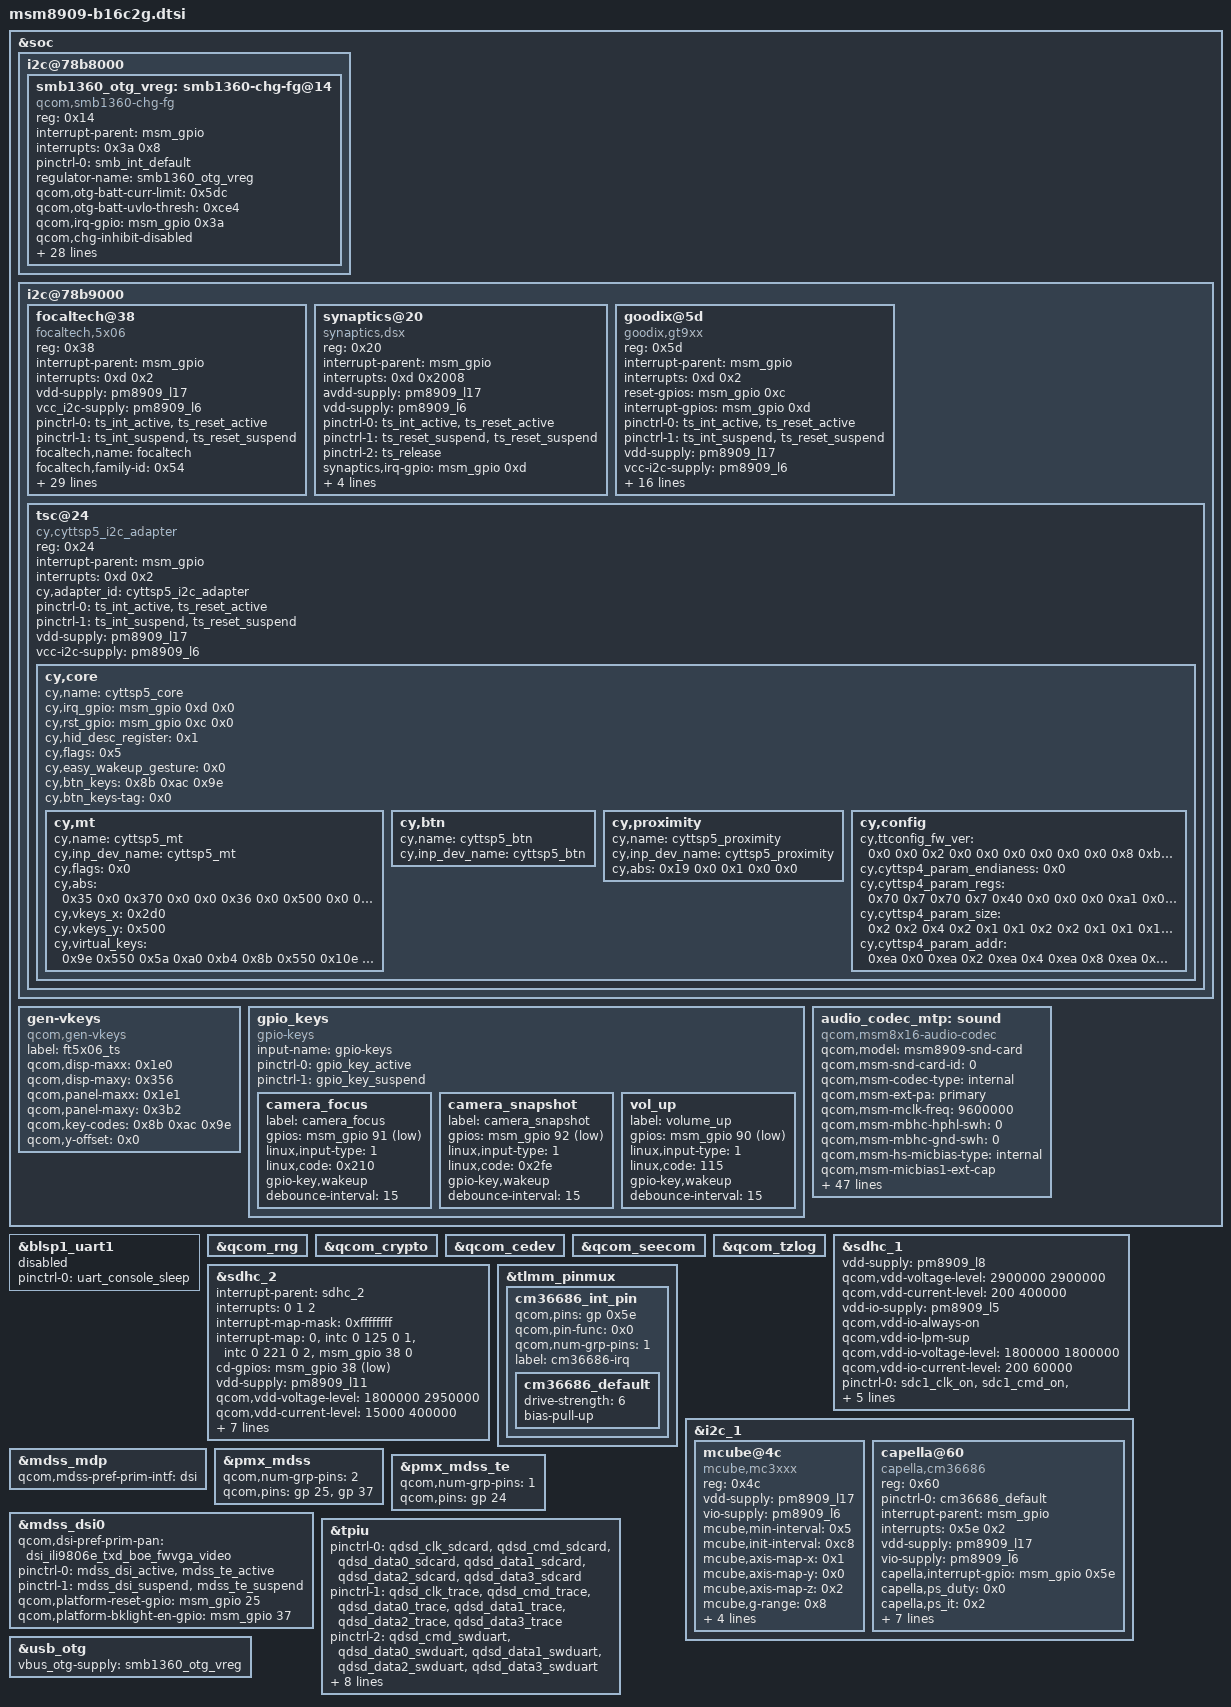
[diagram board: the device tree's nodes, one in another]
/* Copyright (c) 2014-2015, The Linux Foundation. All rights reserved.
 *
 * This program is free software; you can redistribute it and/or modify
 * it under the terms of the GNU General Public License version 2 and
 * only version 2 as published by the Free Software Foundation.
 *
 * This program is distributed in the hope that it will be useful,
 * but WITHOUT ANY WARRANTY; without even the implied warranty of
 * MERCHANTABILITY or FITNESS FOR A PARTICULAR PURPOSE.  See the
 * GNU General Public License for more details.
 */

#include "../msm8909-camera-sensor-mtp.dtsi"

&soc {
	/*
	 * DT node to add support for SMB136x charger and integrate
	 * with VM-BMS.
	 */
	i2c@78b8000 {
		smb1360_otg_vreg: smb1360-chg-fg@14 {
			compatible = "qcom,smb1360-chg-fg";
			reg = <0x14>;
			interrupt-parent = <&msm_gpio>;
			interrupts = <0x3a 0x8>;
			pinctrl-names = "default";
			pinctrl-0 = <&smb_int_default>;
			regulator-name = "smb1360_otg_vreg";
			qcom,otg-batt-curr-limit = <0x5dc>;
			qcom,otg-batt-uvlo-thresh = <0xce4>;
			qcom,irq-gpio = <&msm_gpio 0x3a 0x8>;
			qcom,chg-inhibit-disabled;
			qcom,rsense-10mhom;
			qcom,cpu0-sensor-name = "tsens_tz_sensor3";
			qcom,cpu0-temp-max = <0x38>;
			qcom,cpu0-temp-min = <0x34>;
			qcom,qpnp-vadc = <&pm8909_vadc>;
			qcom,float-voltage-mv = <0x10fe>;
			qcom,iterm-ma = <0x64>;
			qcom,recharge-thresh-mv = <0x64>;
			qcom,thermal-mitigation = <0x5dc 0x2bc 0x258 0x0>;
			qcom,charging-timeout = <0x600>;
			qcom,fg-cutoff-voltage-mv = <0xd48>;
			qcom,fg-voltage-empty-mv = <0xcb2>;
			qcom,fg-batt-capacity-mah = <0x76c>;
			qcom,fg-cc-soc-coeff = <0x8850>;
			qcom,fg-auto-recharge-soc = <0x63>;
			qcom,fg-reset-thresold-mv = <0x32>;
			qcom,shdn-after-pwroff;
			qcom,fg-reset-at-pon;
			qcom,config-hard-thresholds;
			qcom,cold-bat-decidegc = <0xffffffb0>;
			qcom,hot-bat-decidegc = <0x230>;
			qcom,soft-jeita-supported;
			qcom,warm-bat-decidegc = <0x1c2>;
			qcom,cool-bat-decidegc = <0x64>;
			qcom,cool-bat-mv = <0x10fe>;
			qcom,warm-bat-mv = <0x10fe>;
			qcom,cool-bat-ma = <0x190>;
			qcom,warm-bat-ma = <0x258>;
		};
	};

	i2c@78b9000 { /* BLSP1 QUP5 */
		focaltech@38 {
			compatible = "focaltech,5x06";
			reg = <0x38>;
			interrupt-parent = <&msm_gpio>;
			interrupts = <0xd 0x2>;
			vdd-supply = <&pm8909_l17>;
			vcc_i2c-supply = <&pm8909_l6>;
			pinctrl-names = "pmx_ts_active", "pmx_ts_suspend";
			pinctrl-0 = <&ts_int_active &ts_reset_active>;
			pinctrl-1 = <&ts_int_suspend &ts_reset_suspend>;
			focaltech,name = "focaltech";
			focaltech,family-id = <0x54>;
			focaltech,reset-gpio = <&msm_gpio 0xc 0x0>;
			focaltech,irq-gpio = <&msm_gpio 0xd 0x2>;
			focaltech,display-coords = <0x0 0x0 0x1e0 0x356>;
			focaltech,panel-coords = <0x0 0x0 0x1e0 0x356>;
			focaltech,button-map = <0x8b 0xac 0x9e>;
			focaltech,gesture-func-map = <0x1fd 0x1fe 0x1ff 0x200 0x201 0x202 0x203 0x204 0x208 0x207>;
			focaltech,gesture-figure-map = <0x24 0x52 0x51 0x30 0x54 0x31 0x46 0x41 0x32 0x33>;
			focaltech,gesture-reg-map = <0xd1 0xd2 0xd5 0xd6 0xd7 0xd8>;
			focaltech,gesture-reg-value-map = <0x30 0x1f 0x42 0x16 0x0 0x20>;
			focaltech,fw-rawdata-range = <0x0 0x0>;
			focaltech,no-force-update;
			focaltech,i2c-pull-up;
			focaltech,group-id = <0x1>;
			focaltech,hard-reset-delay-ms = <0x5>;
			focaltech,soft-reset-delay-ms = <0xc8>;
			focaltech,num-max-touches = <0x5>;
			focaltech,fw-name = "fw_ft5x06_0xFF.bin";
			focaltech,fw-delay-aa-ms = <0x2>;
			focaltech,fw-delay-55-ms = <0x2>;
			focaltech,fw-upgrade-id1 = <0x54>;
			focaltech,fw-upgrade-id2 = <0x2c>;
			focaltech,fw-delay-readid-ms = <0x14>;
			focaltech,fw-delay-era-flsh-ms = <0xbb8>;
			focaltech,fw-panelid-command = <0x300d784>;
			focaltech,touch-area-param = <0x7>;
		};

		synaptics@20 {
			compatible = "synaptics,dsx";
			reg = <0x20>;
			interrupt-parent = <&msm_gpio>;
			interrupts = <0xd 0x2008>;
			avdd-supply = <&pm8909_l17>;
			vdd-supply = <&pm8909_l6>;
			pinctrl-names = "pmx_ts_active", "pmx_ts_suspend", "pmx_ts_release";
			pinctrl-0 = <&ts_int_active &ts_reset_active>;
			pinctrl-1 = <&ts_reset_suspend &ts_reset_suspend>;
			pinctrl-2 = <&ts_release>;
			synaptics,irq-gpio = <&msm_gpio 0xd 0x2008>;
			synaptics,reset-gpio = <&msm_gpio 0xc 0x0>;
			synaptics,disable-gpios;
			synaptics,display-coords = <0x0 0x0 0x2cf 0x4ff>;
			synaptics,panel-coords = <0x0 0x0 0x2cf 0x57d>;
		};

		goodix@5d {
			compatible = "goodix,gt9xx";
			reg = <0x5d>;
			interrupt-parent = <&msm_gpio>;
			interrupts = <0xd 0x2>;
			reset-gpios = <&msm_gpio 0xc 0x0>;
			interrupt-gpios = <&msm_gpio 0xd 0x0>;
			pinctrl-names = "pmx_ts_active", "pmx_ts_suspend";
			pinctrl-0 = <&ts_int_active &ts_reset_active>;
			pinctrl-1 = <&ts_int_suspend &ts_reset_suspend>;
			vdd-supply = <&pm8909_l17>;
			vcc-i2c-supply = <&pm8909_l6>;
			goodix,panel-coords = <0x0 0x0 0x2d0 0x500>;
			goodix,display-coords = <0x0 0x0 0x2d0 0x500>;
			goodix,button-map = <0x8b 0xac 0x9e>;
			goodix,gesture-map = <0x1fd 0x1fe 0x1ff 0x200 0x201 0x202 0x203 0x204 0x205 0x206>;
			goodix,gesture-key = <0xcc 0x3e 0x63 0x6f 0x76 0x77 0x73 0x7a 0x6d 0x5e>;
			goodix,product-id = "9157";
			goodix,cfg-data1 = [4a d0 02 00 05 0a 35 41 01 42 28 0c 53 35 03 07 00 00 1f 7e 00 00 06 12 18 1e 14 8b 0a 0c 34 00 d3 07 00 00 00 ba 33 11 3c 01 00 00 00 00 00 00 00 00 2a 31 4e 54 c5 01 00 14 00 04 82 33 00 79 38 00 71 3d 00 6a 43 00 64 4a 00 64 10 38 50 00 f0 4a 3a ff ff 27 00 00 00 00 00 00 00 00 00 00 00 00 00 0a 14 04 05 10 32 64 09 14 00 00 4b 32 02 04 06 08 0a 0c 0e 10 12 14 16 18 ff ff 00 00 00 00 00 00 00 00 00 00 00 23 00 02 00 00 1e 1f 1d 20 1c 21 18 22 24 16 13 0a 08 12 06 10 04 0f 02 0c 00 ff ff ff ff ff 00 00 00 f6 ff ff ff ff ff ff ff ff 8f ff ff ff 5a 01];
			goodix,cfg-data2 = [48 d0 02 00 05 05 35 41 01 42 28 0c 55 37 03 07 00 00 1f 7e 00 00 06 12 18 1e 14 8b 0a 0c 34 00 d3 07 00 00 00 ba 33 11 3c 01 00 00 00 00 00 00 00 00 2a 31 4e 54 c5 01 00 14 00 04 82 33 00 79 38 00 71 3d 00 6a 43 00 64 4a 00 64 10 38 50 00 f0 4a 3a ff ff 27 00 00 00 00 00 00 00 00 00 00 00 00 00 0a 0f 04 26 00 21 84 0c 14 00 00 4b 32 02 04 06 08 0a 0c 0e 10 12 14 16 18 ff ff 1f ff ff ff ff ff ff ff ff 00 00 23 00 02 ff 00 24 16 22 18 21 1c 20 1d 1e 1f 13 02 04 12 06 10 08 0f 0a 0c 00 ff ff ff ff ff 00 00 00 f4 ff ff ff ff ff ff ff ff 4f ff ff ff 6b 01];
			goodix,test-data1 = [41 d0 02 00 05 0a 05 41 01 08 28 05 50 32 03 05 00 00 00 00 00 00 00 00 00 00 00 8b 2a 0c 5b 5e 61 07 00 00 00 98 03 2d 00 00 00 00 00 00 00 00 00 00 00 00 00 00 40 00 00 00 00 00 00 00 00 00 00 00 00 00 00 00 00 00 00 00 00 00 10 38 50 00 f0 4a 3a ff ff 27 00 00 00 00 00 00 00 00 00 00 00 00 00 00 00 00 00 00 00 00 00 00 00 00 00 00 02 04 06 08 0a 0c 0e 10 12 14 16 18 ff ff 00 00 00 00 00 00 00 00 00 ff 00 00 00 00 ff 00 1e 1f 1d 20 1c 21 18 22 16 24 13 0a 08 12 06 10 04 0f 02 0c 00 ff ff ff ff ff ff 00 00 fb 00 01 f0 11 00 ff 00 11 e1 00 00 00 a4 01];
			goodix,test-data2 = [00 d0 02 38 04 05 05 41 01 08 28 05 50 32 03 05 00 00 00 00 00 00 00 00 00 00 00 8b 0a 0c 79 7b d3 07 00 00 00 99 03 11 00 00 00 00 00 00 00 00 00 00 00 00 00 00 40 00 00 00 00 00 00 00 00 00 00 00 00 00 00 00 00 00 00 00 00 00 10 38 50 00 f0 4a 3a ff ff 27 00 00 00 00 00 00 00 00 00 00 00 00 00 00 00 00 00 00 00 00 00 00 00 00 00 00 02 04 06 08 0a 0c 0e 10 12 14 16 18 ff ff 1f ff ff ff ff ff ff ff ff 00 ff ff ff ff ff 00 24 16 22 18 21 1c 20 1d 1e 1f 13 02 04 12 06 10 08 0f 0a 0c 00 ff ff ff ff ff 00 ff ff fb ff ff ff ff ff ff ff ff bf ff ff ff 6d 01];
		};

		tsc@24 {
			compatible = "cy,cyttsp5_i2c_adapter";
			reg = <0x24>;
			interrupt-parent = <&msm_gpio>;
			interrupts = <0xd 0x2>;
			cy,adapter_id = "cyttsp5_i2c_adapter";
			pinctrl-names = "pmx_ts_active", "pmx_ts_suspend";
			pinctrl-0 = <&ts_int_active &ts_reset_active>;
			pinctrl-1 = <&ts_int_suspend &ts_reset_suspend>;
			vdd-supply = <&pm8909_l17>;
			vcc-i2c-supply = <&pm8909_l6>;

			cy,core {
				cy,name = "cyttsp5_core";
				cy,irq_gpio = <&msm_gpio 0xd 0x0>;
				cy,rst_gpio = <&msm_gpio 0xc 0x0>;
				cy,hid_desc_register = <0x1>;
				cy,flags = <0x5>;
				cy,easy_wakeup_gesture = <0x0>;
				cy,btn_keys = <0x8b 0xac 0x9e>;
				cy,btn_keys-tag = <0x0>;

				cy,mt {
					cy,name = "cyttsp5_mt";
					cy,inp_dev_name = "cyttsp5_mt";
					cy,flags = <0x0>;
					cy,abs = <0x35 0x0 0x370 0x0 0x0 0x36 0x0 0x500 0x0 0x0 0x3a 0x0 0xff 0x0 0x0 0xffff 0x0 0xff 0x0 0x0 0x39 0x0 0xf 0x0 0x0 0x30 0x0 0xff 0x0 0x0 0x31 0x0 0xff 0x0 0x0 0x34 0xffffff81 0x7f 0x0 0x0 0x37 0x0 0x1 0x0 0x0 0x19 0x0 0xff 0x0 0x0>;
					cy,vkeys_x = <0x2d0>;
					cy,vkeys_y = <0x500>;
					cy,virtual_keys = <0x9e 0x550 0x5a 0xa0 0xb4 0x8b 0x550 0x10e 0xa0 0xb4 0xac 0x550 0x1c2 0xa0 0xb4 0xd9 0x550 0x276 0xa0 0xb4>;
				};

				cy,btn {
					cy,name = "cyttsp5_btn";
					cy,inp_dev_name = "cyttsp5_btn";
				};

				cy,proximity {
					cy,name = "cyttsp5_proximity";
					cy,inp_dev_name = "cyttsp5_proximity";
					cy,abs = <0x19 0x0 0x1 0x0 0x0>;
				};

				cy,config {
					cy,ttconfig_fw_ver = <0x0 0x0 0x2 0x0 0x0 0x0 0x0 0x0 0x0 0x8 0xbf 0x3d 0xc 0x7 0x12 0x9c 0x0 0xa1>;
					cy,cyttsp4_param_endianess = <0x0>;
					cy,cyttsp4_param_regs = <0x70 0x7 0x70 0x7 0x40 0x0 0x0 0x0 0xa1 0x0 0x3 0x0 0x7c 0x14 0xfc 0x21 0x14 0x0 0x1 0x8 0x3 0x0 0x0 0x0 0x64 0x0 0xe8 0x3 0x1 0xc 0x64 0x8 0xf4 0x1 0x1e 0x0 0x88 0x13 0x3 0x3c 0x14 0x3c 0x0 0x0 0x0 0xa 0x0 0x0 0x0 0x0 0x0 0x0 0x0 0x0 0x0 0xff 0x0 0x1 0x0 0x1 0x32 0x0 0xfa 0x0 0x0 0x0 0x0 0x0 0x0 0x0 0x0 0x0 0x0 0x0 0x0 0x0 0x0 0x0 0x0 0x0 0x1 0x0 0x0 0x0 0x0 0x0 0x0 0x0 0x64 0x0 0x2 0x1 0x0 0x0 0x0 0x0 0x0 0x0 0x6 0x6 0xb4 0x0 0x5a 0x0 0xe8 0x3 0x0 0x0 0x1 0x0 0x7f 0x0 0x2d 0x0 0x1 0x60 0x0 0x80 0x1 0xff 0x0 0x0 0x0 0x0 0x30 0x0 0x90 0x1 0x0 0x7f 0x4 0x1 0x1f 0x2 0x0 0x0 0x38 0x0 0x90 0x1 0x0 0x7f 0x4 0x1 0x1f 0x2 0x0 0x0 0x3c 0x0 0x90 0x1 0x0 0x7f 0x4 0x1 0x1f 0x2 0x0 0x0 0x3f 0x0 0x90 0x1 0x0 0x7f 0x4 0x1 0x1f 0x2 0x0 0x0 0x4b 0x0 0x90 0x1 0x0 0x7f 0x4 0x1 0x1f 0x2 0x0 0x0 0x2c 0x0 0x0 0x0 0xf0 0x0 0x0 0x0 0x2 0x0 0x0 0x0 0x1 0x0 0x0 0x0 0xff 0xff 0x1 0x0 0xf0 0x0 0x0 0x0 0x2 0x0 0x0 0x0 0x2 0x0 0x0 0x0 0xff 0xff 0x1 0x0 0x0 0xc 0x0 0x0 0x0 0x0 0x0 0x0 0x0 0x0 0x0 0x0 0x10 0x0 0x0 0x0 0x0 0x0 0x0 0x0 0x4 0x17 0x3 0x0 0x0 0x0 0x0 0x0 0xe0 0x1 0x0 0x0 0x20 0x3 0x0 0x0 0x0 0x0 0x0 0x0 0x0 0x0 0x2 0x1 0x2 0x58 0x80 0x0 0x1a 0x0 0x4 0x0 0x1a 0x0 0x0 0x4 0x38 0x0 0x5 0x4 0xf 0x28 0x0 0x0 0x0 0x0 0x0 0x0 0x8 0x78 0x2 0x0 0x5 0x0 0x2 0x0 0x4a 0x1 0x0 0x0 0x82 0x0 0x0 0x0 0x4a 0x1 0x0 0x0 0x82 0x0 0x0 0x0 0x78 0x0 0x0 0x0 0xb4 0x0 0x0 0x0 0x78 0x0 0x0 0x0 0xb4 0x0 0x0 0x0 0x0 0xa 0x64 0x0 0x78 0x0 0x3 0x4 0x3 0x68 0x80 0x40 0x4 0x19 0x0 0x0 0x28 0x28 0x28 0x28 0x28 0x28 0x28 0x28 0xa 0x14 0x0 0x0 0x0 0x0 0x0 0x0 0x0 0x0 0x0 0x0 0x77 0x70 0x0 0x1 0x0 0x1 0xa 0x0 0xa 0x0 0x14 0x0 0x14 0x0 0x28 0x0 0x77 0x70 0x1 0x1 0x1 0x1 0x14 0x0 0x14 0x0 0x14 0x0 0x14 0x0 0x3c 0x0 0x0 0x0 0x0 0x0 0x0 0x0 0x0 0x0 0x0 0x0 0x0 0x0 0x0 0x0 0x0 0x0 0xc8 0x0 0x0 0x0 0x5 0x5 0x14 0x3 0xf 0x0 0xa 0x0 0xa 0x0 0xa 0x0 0xa 0x0 0x5 0x0 0x50 0x50 0x50 0x50 0x50 0x3 0x78 0x0 0xc 0x0 0xc 0x0 0xc 0x0 0x0 0x1 0x1 0x0 0x40 0x1f 0x40 0x1f 0xa 0xa 0x0 0x0 0x0 0x0 0x0 0x0 0x0 0x0 0x8 0x0 0x0 0x0 0x1 0x0 0x0 0x0 0x0 0x0 0x0 0x0 0x0 0x0 0x0 0x0 0x1 0x0 0x0 0x0 0x1 0x0 0x0 0x0 0x0 0x0 0x0 0x0 0x0 0xc3 0x13 0x70 0xff 0xaa 0x10 0x0 0x0 0x5 0x20 0x1 0x0 0x5 0x20 0x1 0x0 0x4 0x0 0x0 0x0 0xff 0x0 0x0 0x0 0xa 0x3 0xc0 0xc6 0x0 0x12 0xb 0x1d 0x3 0x1 0x1 0x1 0x2 0x90 0x1 0xf4 0x1 0x2c 0x1 0x2c 0x1 0xf4 0x1 0x1f 0x1f 0x1f 0x1f 0x51 0x0 0xa0 0x0 0x3d 0x0 0xa0 0x0 0x32 0x64 0x32 0x20 0x64 0x4 0x0 0xb 0x1f 0xb 0x1f 0x2 0x0 0x0 0x0 0x10 0x4 0x0 0x1f 0x0 0x3c 0x0 0xf 0x0 0x7f 0x14 0x0 0x0 0x0 0x0 0x0 0x0 0x0 0x0 0x0 0xfc 0x1f 0x0 0x0 0x0 0x0 0x0 0x0 0x0 0x0 0x0 0x0 0x0 0x0 0x80 0xff 0x0 0x0 0xff 0x1 0x0 0x0 0x0 0x0 0x0 0x0 0x0 0x0 0x0 0x0 0x80 0xff 0xfc 0x1f 0xff 0x3 0x0 0x0 0x0 0x0 0x0 0x0 0x0 0x0 0x0 0x24 0x23 0x22 0x21 0x20 0x1f 0x1e 0x1d 0x1c 0x1b 0x1a 0x17 0x16 0x15 0x14 0x13 0x12 0x11 0x10 0xf 0x28 0x29 0x2a 0x2b 0x2c 0x2d 0x2e 0x2f 0x30 0x31 0x2b 0x2c 0x2d 0x2e 0x2f 0x30 0x31 0x7 0x6 0x5 0x4 0x3 0x2 0x1 0x0 0x0 0x0 0x0 0x0 0x0 0x0 0x0 0x0 0x0 0x0 0x0 0x0 0x0 0x0 0x0 0x0 0x0 0x0 0x0 0x0 0x0 0x0 0x0 0x0 0x0 0x0 0x0 0x7 0x0 0x0 0x0 0x0 0x0 0x0 0x0 0x0 0x20 0x0 0x20 0x0 0x20 0x0 0xe0 0x0 0x0 0x0 0x0 0x0 0x0 0x0 0x0 0x0 0x0 0x0 0x0 0x0 0x0 0x0 0x0 0x0 0x0 0x0 0x0 0x0 0x0 0x0 0x0 0x0 0x0 0x0 0x0 0x0 0x0 0x0 0x0 0x0 0x0 0x0 0x0 0x0 0x0 0x0 0x0 0x0 0x0 0x0 0x0 0x0 0x0 0x0 0x0 0x0 0x0 0x0 0x0 0x0 0x0 0x0 0x0 0x0 0x0 0x0 0x0 0x0 0x0 0x0 0x0 0x0 0x0 0x0 0x0 0x0 0x0 0x0 0x0 0x0 0x0 0x0 0xfc 0x1f 0x0 0x0 0x0 0x0 0x0 0x0 0x0 0x0 0x0 0x0 0x0 0x0 0xff 0x7 0x0 0x0 0x0 0x0 0x0 0xff 0xb 0xff 0xff 0xff 0xff 0xff 0xff 0xff 0xff 0xa 0x9 0x8 0x7 0x6 0x5 0x4 0x3 0x2 0x1 0x0 0xff 0xff 0x0 0x0 0x80 0xff 0x0 0x0 0xff 0x1 0x0 0x0 0x0 0x0 0x0 0x0 0x0 0x0 0x0 0xbe 0xf7 0x1f 0x0 0x0 0x0 0x0 0x0 0xff 0x12 0xff 0xf 0xe 0xd 0xc 0xb 0xff 0x13 0x12 0x11 0x10 0xff 0x14 0x15 0x16 0x17 0x18 0x19 0x1a 0x1b 0x1c 0x0 0x0 0x0 0x0 0x88 0x8 0x0 0x0 0x0 0x0 0x0 0x0 0x0 0x0 0x0 0x0 0x0 0x0 0x22 0x2 0x0 0x0 0x0 0x0 0x0 0xff 0x3 0xff 0xff 0xff 0xff 0xff 0xff 0xff 0xff 0xff 0x2 0xff 0xff 0xff 0x1 0xff 0xff 0xff 0x0 0xff 0xff 0xff 0x0 0x0 0x0 0x0 0x0 0x0 0x0 0x0 0x0 0x0 0x0 0x0 0x0 0x0 0x0 0x0 0x0 0x0 0x0 0x0 0x0 0x0 0x0 0x0 0x0 0xff 0x0 0xff 0xff 0xff 0xff 0xff 0xff 0xff 0xff 0xff 0xff 0xff 0xff 0xff 0xff 0xff 0xff 0xff 0xff 0xff 0xff 0xff 0x0 0x0 0x0 0x0 0x0 0x0 0x0 0x0 0x0 0x0 0x0 0x0 0x0 0x0 0x0 0x0 0x0 0x0 0x0 0x0 0x0 0x0 0x0 0x0 0x0 0x0 0x0 0x0 0x0 0x0 0x0 0x0 0x0 0x0 0x0 0x0 0x0 0x0 0x0 0x0 0x0 0x0 0x0 0x0 0x0 0x0 0x0 0x0 0x0 0x0 0x0 0xe0 0x0 0x0 0x0 0x0 0x0 0x0 0x0 0x10 0x0 0x0 0x0 0x0 0x0 0x0 0x0 0xd0 0x0 0x0 0x0 0x0 0x0 0x0 0x0 0x20 0x0 0x0 0x0 0x0 0x0 0x0 0x0 0xb0 0x0 0x0 0x0 0x0 0x0 0x0 0x0 0x40 0x0 0x0 0x0 0x0 0x0 0x0 0x0 0x70 0x0 0x0 0x0 0x0 0x0 0x0 0x0 0x80 0x0 0x0 0x0 0x0 0x0 0x0 0x0 0xe 0x0 0x0 0x0 0x0 0x0 0x0 0x0 0x1 0x0 0x0 0x0 0x0 0x0 0x0 0x0 0xd 0x0 0x0 0x0 0x0 0x0 0x0 0x0 0x2 0x0 0x0 0x0 0x0 0x0 0x0 0x0 0xb 0x0 0x0 0x0 0x0 0x0 0x0 0x0 0x4 0x0 0x0 0x0 0x0 0x0 0x0 0x0 0x7 0x0 0x0 0x0 0x0 0x0 0x0 0x0 0x8 0x0 0x0 0x0 0x0 0x0 0x0 0x80 0x0 0x0 0x0 0x3 0x0 0x0 0x0 0x0 0x0 0x0 0x0 0x4 0x0 0x0 0x0 0x80 0x0 0x0 0x0 0x5 0x0 0x0 0x0 0x0 0x0 0x0 0x0 0x2 0x0 0x0 0x0 0x80 0x0 0x0 0x0 0x6 0x0 0x0 0x0 0x0 0x0 0x0 0x0 0x1 0x0 0x0 0x0 0x0 0x0 0x0 0x0 0x7 0x0 0x0 0x0 0x80 0x0 0x0 0x0 0x0 0x0 0x0 0x0 0x0 0x0 0x0 0x0 0x38 0x0 0x0 0x0 0x0 0x0 0x0 0x0 0x40 0x0 0x0 0x0 0x0 0x0 0x0 0x0 0x58 0x0 0x0 0x0 0x0 0x0 0x0 0x0 0x20 0x0 0x0 0x0 0x0 0x0 0x0 0x0 0x68 0x0 0x0 0x0 0x0 0x0 0x0 0x0 0x10 0x0 0x0 0x0 0x0 0x0 0x0 0x0 0x70 0x0 0x0 0x0 0x0 0x0 0x0 0x0 0x8 0x0 0x0 0x0 0x0 0x0 0x0 0x0 0xe0 0x0 0x0 0x0 0x0 0x0 0x0 0x0 0x0 0x1 0x0 0x0 0x0 0x0 0x0 0x0 0x60 0x1 0x0 0x0 0x0 0x0 0x0 0x0 0x80 0x0 0x0 0x0 0x0 0x0 0x0 0x0 0xa0 0x1 0x0 0x0 0x0 0x0 0x0 0x0 0x40 0x0 0x0 0x0 0x0 0x0 0x0 0x0 0xc0 0x1 0x0 0x0 0x0 0x0 0x0 0x0 0x20 0x0 0x0 0xc0 0x0 0x0 0x0 0x0 0x0 0x2 0x0 0x20 0x0 0x0 0x0 0x0 0x0 0x0 0x0 0xa0 0x0 0x0 0x0 0x0 0x0 0x2 0x0 0x40 0x0 0x0 0x0 0x0 0x0 0x0 0x0 0x60 0x0 0x0 0x0 0x0 0x0 0x2 0x0 0x80 0x0 0x0 0x0 0x0 0x0 0x0 0x0 0xe0 0x0 0x0 0x0 0x0 0x0 0x0 0x0 0x0 0x0 0x0 0x0 0x0 0x0 0x2 0x0 0x1c 0x0 0x0 0x0 0x0 0x0 0x0 0x0 0x2 0x0 0x0 0x0 0x0 0x0 0x0 0x0 0x1a 0x0 0x0 0x0 0x0 0x0 0x0 0x0 0x4 0x0 0x0 0x0 0x0 0x0 0x0 0x0 0x16 0x0 0x0 0x0 0x0 0x0 0x0 0x0 0x8 0x0 0x0 0x0 0x0 0x0 0x0 0x0 0xe 0x0 0x0 0x0 0x0 0x0 0x0 0x0 0x10 0x0 0x0 0x0 0x0 0x0 0x0 0x0 0x1 0x0 0x0 0x0 0x0 0x0 0xc 0x0 0x0 0x0 0x0 0x0 0x0 0x0 0x10 0x0 0x1 0x0 0x0 0x0 0x0 0x0 0x14 0x0 0x0 0x0 0x0 0x0 0x0 0x0 0x8 0x0 0x1 0x0 0x0 0x0 0x0 0x0 0x18 0x0 0x0 0x0 0x0 0x0 0x0 0x0 0x4 0x0 0x0 0x0 0x0 0x0 0x0 0x0 0x1c 0x0 0x1 0x0 0x0 0x0 0x0 0x0 0x0 0x0 0x0 0x0 0x0 0x0 0x0 0x0 0xe0 0x0 0x0 0x0 0x0 0x0 0x0 0x0 0x0 0x1 0x0 0x0 0x0 0x0 0x0 0x0 0x60 0x1 0x0 0x0 0x0 0x0 0x0 0x0 0x80 0x0 0x0 0x0 0x0 0x0 0x0 0x0 0xa0 0x1 0x0 0x0 0x0 0x0 0x0 0x0 0x40 0x0 0x0 0x0 0x0 0x0 0x0 0x0 0xc0 0x1 0x0 0x0 0x0 0x0 0x0 0x0 0x20 0x0 0x0 0x0 0x0 0x0 0x0 0x0 0xc0 0x1 0x0 0x0 0x0 0x0 0x0 0x0 0x0 0x2 0x0 0x0 0x0 0x0 0x0 0x0 0xc0 0x2 0x0 0x0 0x0 0x0 0x0 0x0 0x0 0x1 0x0 0x0 0x0 0x0 0x0 0x0 0x40 0x3 0x0 0x0 0x0 0x0 0x0 0x0 0x80 0x0 0x0 0x0 0x0 0x0 0x0 0x0 0x80 0x3 0x0 0x0 0x0 0x0 0x0 0x0 0x40 0x0 0x5a 0x5a 0x32 0x4b 0x23 0x0 0x0 0x0 0x0 0x40 0x8 0x5 0x4 0x14 0x28 0x0 0xa 0x0 0x80 0x0 0x16 0x0 0xfa 0x0 0x32 0x0 0xc0 0x1 0xf0 0x0 0x28 0x0 0xd0 0x7 0xa0 0x0 0xd0 0x7 0x28 0x0 0x18 0x0 0x8 0x0 0x0 0x19 0xf0 0x0 0x55 0x55 0x0 0x1 0xa 0x0 0xa 0x0 0xa 0x0 0x28 0x0 0xf 0x0 0xa 0x0 0x5 0x5 0x8 0x78 0xf0 0x0 0x0 0x0 0x2 0x0 0x0 0x0 0x1 0x0 0x0 0x0 0x4 0x17 0x3 0x0 0xff 0xff 0x1 0x1 0x1 0x1 0x40 0x0 0x0 0x0 0x0 0x0 0x90 0x1 0x5e 0x1 0x88 0x13 0x98 0x3a 0xb8 0xb 0xb8 0xb 0xc8 0x0 0xf 0x1e 0x96 0x28 0x0 0x0 0x0 0x0 0x0 0x0 0x3 0x3 0xa 0x3 0x23 0x5 0x40 0x0 0x60 0xea 0x0 0x0 0x90 0x5f 0x1 0x0 0x60 0xea 0x0 0x0 0x30 0x9 0x9f 0x24 0x45 0x33 0xdc 0x5 0x30 0x75 0x5 0x0 0x32 0x0 0x28 0x0 0xa 0x0 0x2 0x0 0x0 0x0 0x0 0x0 0xa 0x0 0x1 0x0 0x4 0x0 0x1e 0x0 0x14 0x0 0x28 0x0 0x0 0x0 0xa 0x0 0x0 0x0 0x40 0x0 0x8 0x0 0x78 0x0 0x14 0x0 0xa 0x0 0x1e 0x0 0x14 0x0 0x2 0x0 0xa 0x0 0xa 0x0 0xa 0x0 0x32 0x0 0x3c 0x0 0xa0 0x0 0x96 0x0 0x4 0x0 0x0 0x0 0x1 0x0 0x40 0x5 0xdc 0x5 0xac 0xd 0xf4 0x1 0xfa 0x0 0xc8 0x0 0x0 0x0 0xf0 0xb1>;
					cy,cyttsp4_param_size = <0x2 0x2 0x4 0x2 0x1 0x1 0x2 0x2 0x1 0x1 0x1 0x1 0x2 0x1 0x1 0x2 0x2 0x1 0x1 0x1 0x1 0x2 0x1 0x1 0x2 0x1 0x1 0x1 0x1 0x1 0x1 0x1 0x1 0x2 0x2 0x2 0x1 0x1 0x1 0x1 0x1 0x1 0x1 0x1 0x2 0x2 0x2 0x2 0x2 0x2 0x2 0x2 0x2 0x2 0x1 0x1 0x1 0x5 0x2 0x1 0x1 0x2 0x1 0x1 0x1 0x1 0x1 0x1 0x2 0x2 0x4 0x2 0x1 0x1 0x2 0x1 0x1 0x2 0x1 0x1 0x4 0x2 0x2 0x1 0x1 0x1 0x1 0x1 0x1 0x2 0x2 0x2 0x1 0x1 0x1 0x1 0x1 0x1 0x2 0x2 0x2 0x1 0x1 0x1 0x1 0x1 0x1 0x2 0x2 0x2 0x1 0x1 0x1 0x1 0x1 0x1 0x2 0x2 0x2 0x1 0x1 0x1 0x1 0x1 0x1 0x2 0x4 0x4 0x4 0x4 0x1 0x1 0x1 0x1 0x4 0x4 0x4 0x1 0x1 0x1 0x1 0x1 0x1 0x1 0x1 0x1 0x1 0x6 0x4 0x4 0x4 0x1 0x3 0x4 0x4 0x2 0x1 0x1 0x1 0x1 0x1 0x1 0x1 0x1 0x2 0x2 0x2 0x2 0x1 0x1 0x2 0x1 0x1 0x1 0x1 0x6 0x1 0x1 0x2 0x2 0x2 0x4 0x4 0x4 0x4 0x4 0x4 0x4 0x4 0x1 0x1 0x2 0x2 0x1 0x1 0x1 0x1 0x1 0x1 0x1 0x1 0x2 0x1 0x1 0x1 0x1 0x1 0x1 0x1 0x1 0x1 0x1 0x1 0x5 0x4 0x2 0x1 0x1 0x1 0x1 0x2 0x2 0x2 0x2 0x2 0x2 0x1 0x1 0x1 0x1 0x2 0x2 0x2 0x2 0x2 0x2 0x1 0x1 0x1 0x1 0x2 0x2 0x2 0x2 0x2 0x4 0x1 0x1 0x1 0x1 0x2 0x2 0x2 0x2 0x2 0x2 0x1 0x1 0x1 0x1 0x1 0x1 0x2 0x2 0x2 0x2 0x1 0x1 0x1 0x1 0x2 0x2 0x1 0x1 0x1 0x1 0x6 0x4 0x1 0x1 0x2 0x4 0x4 0x4 0x4 0x4 0x4 0x4 0x4 0x4 0x4 0x4 0x4 0x2 0x1 0x1 0x1 0x1 0x1 0x1 0x1 0x1 0x2 0x2 0x2 0x2 0x2 0x1 0x1 0x1 0x1 0x2 0x2 0x2 0x2 0x1 0x1 0x1 0x1 0x1 0x1 0x1 0x1 0x1 0x1 0x1 0x1 0x1 0x1 0x1 0x1 0x1 0x1 0x1 0x1 0x2 0x2 0x1 0x1 0x6 0x30 0x41 0x7 0x8 0x50 0xf0 0x280 0x1 0x1 0x1 0x1 0x1 0x3 0x1 0x1 0x1 0x1 0x1 0x1 0x2 0x2 0x2 0x2 0x2 0x2 0x2 0x2 0x2 0x2 0x2 0x2 0x2 0x2 0x2 0x1 0x1 0x2 0x2 0x1 0x1 0x2 0x2 0x2 0x2 0x2 0x2 0x1 0x1 0x1 0x1 0x4 0x4 0x4 0x4 0x1 0x1 0x1 0x1 0x1 0x1 0x1 0x5 0x2 0x2 0x2 0x2 0x2 0x2 0x2 0x1 0x1 0x1 0x1 0x6 0x1 0x1 0x1 0x1 0x1 0x1 0x1 0x1 0x4 0x4 0x4 0x1 0x1 0x2 0x2 0x2 0x2 0x1 0x1 0x2 0x2 0x2 0x2 0x2 0x2 0x2 0x2 0x2 0x2 0x2 0x2 0x2 0x2 0x2 0x2 0x2 0x2 0x2 0x2 0x2 0x2 0x2 0x2 0x2 0x2 0x2 0x2 0x2 0x2 0x2 0x2 0x2 0x1 0x1 0x2 0x2 0x2 0x2 0x2 0x2 0x2>;
					cy,cyttsp4_param_addr = <0xea 0x0 0xea 0x2 0xea 0x4 0xea 0x8 0xea 0xa 0xea 0xb 0xea 0xc 0xea 0xe 0xea 0x10 0xea 0x11 0xea 0x12 0xea 0x13 0xea 0x14 0xea 0x16 0xea 0x17 0xea 0x18 0xea 0x1a 0xea 0x1c 0xea 0x1d 0xea 0x1e 0xea 0x1f 0xea 0x20 0xea 0x22 0xea 0x23 0xea 0x24 0xea 0x26 0xea 0x27 0xea 0x28 0xea 0x29 0xea 0x2a 0xea 0x2b 0xea 0x2c 0xea 0x2d 0xea 0x2e 0xea 0x30 0xea 0x32 0xea 0x34 0xea 0x35 0xea 0x36 0xea 0x37 0xea 0x38 0xea 0x39 0xea 0x3a 0xea 0x3b 0xea 0x3c 0xea 0x3e 0xea 0x40 0xea 0x42 0xea 0x44 0xea 0x46 0xea 0x48 0xea 0x4a 0xea 0x4c 0xea 0x4e 0xea 0x50 0xea 0x51 0xea 0x52 0xea 0x53 0xea 0x58 0xea 0x5a 0xea 0x5b 0xea 0x5c 0xea 0x5e 0xea 0x5f 0xea 0x60 0xea 0x61 0xea 0x62 0xea 0x63 0xea 0x64 0xea 0x66 0xea 0x68 0xea 0x6c 0xea 0x6e 0xea 0x6f 0xea 0x70 0xea 0x72 0xea 0x73 0xea 0x74 0xea 0x76 0xea 0x77 0xea 0x78 0xea 0x7c 0xea 0x7e 0xea 0x80 0xea 0x81 0xea 0x82 0xea 0x83 0xea 0x84 0xea 0x85 0xea 0x86 0xea 0x88 0xea 0x8a 0xea 0x8c 0xea 0x8d 0xea 0x8e 0xea 0x8f 0xea 0x90 0xea 0x91 0xea 0x92 0xea 0x94 0xea 0x96 0xea 0x98 0xea 0x99 0xea 0x9a 0xea 0x9b 0xea 0x9c 0xea 0x9d 0xea 0x9e 0xea 0xa0 0xea 0xa2 0xea 0xa4 0xea 0xa5 0xea 0xa6 0xea 0xa7 0xea 0xa8 0xea 0xa9 0xea 0xaa 0xea 0xac 0xea 0xae 0xea 0xb0 0xea 0xb1 0xea 0xb2 0xea 0xb3 0xea 0xb4 0xea 0xb5 0xea 0xb6 0xea 0xb8 0xea 0xbc 0xea 0xc0 0xea 0xc4 0xea 0xc8 0xea 0xc9 0xea 0xca 0xea 0xcb 0xea 0xcc 0xea 0xd0 0xea 0xd4 0xea 0xd8 0xea 0xd9 0xea 0xda 0xea 0xdb 0xea 0xdc 0xea 0xdd 0xea 0xde 0xea 0xdf 0xea 0xe0 0xea 0xe1 0xea 0xe2 0xea 0xe8 0xea 0xec 0xea 0xf0 0xea 0xf4 0xea 0xf5 0xea 0xf8 0xea 0xfc 0xeb 0x0 0xeb 0x2 0xeb 0x3 0xeb 0x4 0xeb 0x5 0xeb 0x6 0xeb 0x7 0xeb 0x8 0xeb 0x9 0xeb 0xa 0xeb 0xc 0xeb 0xe 0xeb 0x10 0xeb 0x12 0xeb 0x13 0xeb 0x14 0xeb 0x16 0xeb 0x17 0xeb 0x18 0xeb 0x19 0xeb 0x1a 0xeb 0x20 0xeb 0x21 0xeb 0x22 0xeb 0x24 0xeb 0x26 0xeb 0x28 0xeb 0x2c 0xeb 0x30 0xeb 0x34 0xeb 0x38 0xeb 0x3c 0xeb 0x40 0xeb 0x44 0xeb 0x48 0xeb 0x49 0xeb 0x4a 0xeb 0x4c 0xeb 0x4e 0xeb 0x4f 0xeb 0x50 0xeb 0x51 0xeb 0x52 0xeb 0x53 0xeb 0x54 0xeb 0x55 0xeb 0x56 0xeb 0x58 0xeb 0x59 0xeb 0x5a 0xeb 0x5b 0xeb 0x5c 0xeb 0x5d 0xeb 0x5e 0xeb 0x5f 0xeb 0x60 0xeb 0x61 0xeb 0x62 0xeb 0x63 0xeb 0x68 0xeb 0x6c 0xeb 0x6e 0xeb 0x6f 0xeb 0x70 0xeb 0x71 0xeb 0x72 0xeb 0x74 0xeb 0x76 0xeb 0x78 0xeb 0x7a 0xeb 0x7c 0xeb 0x7e 0xeb 0x7f 0xeb 0x80 0xeb 0x81 0xeb 0x82 0xeb 0x84 0xeb 0x86 0xeb 0x88 0xeb 0x8a 0xeb 0x8c 0xeb 0x8e 0xeb 0x8f 0xeb 0x90 0xeb 0x91 0xeb 0x92 0xeb 0x94 0xeb 0x96 0xeb 0x98 0xeb 0x9a 0xeb 0x9c 0xeb 0xa0 0xeb 0xa1 0xeb 0xa2 0xeb 0xa3 0xeb 0xa4 0xeb 0xa6 0xeb 0xa8 0xeb 0xaa 0xeb 0xac 0xeb 0xae 0xeb 0xb0 0xeb 0xb1 0xeb 0xb2 0xeb 0xb3 0xeb 0xb4 0xeb 0xb5 0xeb 0xb6 0xeb 0xb8 0xeb 0xba 0xeb 0xbc 0xeb 0xbe 0xeb 0xbf 0xeb 0xc0 0xeb 0xc1 0xeb 0xc2 0xeb 0xc4 0xeb 0xc6 0xeb 0xc7 0xeb 0xc8 0xeb 0xc9 0xeb 0xca 0xeb 0xd0 0xeb 0xd4 0xeb 0xd5 0xeb 0xd6 0xeb 0xd8 0xeb 0xdc 0xeb 0xe0 0xeb 0xe4 0xeb 0xe8 0xeb 0xec 0xeb 0xf0 0xeb 0xf4 0xeb 0xf8 0xeb 0xfc 0xec 0x0 0xec 0x4 0xec 0x8 0xec 0xa 0xec 0xb 0xec 0xc 0xec 0xd 0xec 0xe 0xec 0xf 0xec 0x10 0xec 0x11 0xec 0x12 0xec 0x14 0xec 0x16 0xec 0x18 0xec 0x1a 0xec 0x1c 0xec 0x1d 0xec 0x1e 0xec 0x1f 0xec 0x20 0xec 0x22 0xec 0x24 0xec 0x26 0xec 0x28 0xec 0x29 0xec 0x2a 0xec 0x2b 0xec 0x2c 0xec 0x2d 0xec 0x2e 0xec 0x2f 0xec 0x30 0xec 0x31 0xec 0x32 0xec 0x33 0xec 0x34 0xec 0x35 0xec 0x36 0xec 0x37 0xec 0x38 0xec 0x39 0xec 0x3a 0xec 0x3b 0xec 0x3c 0xec 0x3e 0xec 0x40 0xec 0x41 0xec 0x42 0xec 0x48 0xec 0x78 0xec 0xb9 0xec 0xc0 0xec 0xc8 0xed 0x18 0xee 0x8 0xf0 0x88 0xf0 0x89 0xf0 0x8a 0xf0 0x8b 0xf0 0x8c 0xf0 0x8d 0xf0 0x90 0xf0 0x91 0xf0 0x92 0xf0 0x93 0xf0 0x94 0xf0 0x95 0xf0 0x96 0xf0 0x98 0xf0 0x9a 0xf0 0x9c 0xf0 0x9e 0xf0 0xa0 0xf0 0xa2 0xf0 0xa4 0xf0 0xa6 0xf0 0xa8 0xf0 0xaa 0xf0 0xac 0xf0 0xae 0xf0 0xb0 0xf0 0xb2 0xf0 0xb4 0xf0 0xb5 0xf0 0xb6 0xf0 0xb8 0xf0 0xba 0xf0 0xbb 0xf0 0xbc 0xf0 0xbe 0xf0 0xc0 0xf0 0xc2 0xf0 0xc4 0xf0 0xc6 0xf0 0xc8 0xf0 0xc9 0xf0 0xca 0xf0 0xcb 0xf0 0xcc 0xf0 0xd0 0xf0 0xd4 0xf0 0xd8 0xf0 0xdc 0xf0 0xdd 0xf0 0xde 0xf0 0xdf 0xf0 0xe0 0xf0 0xe1 0xf0 0xe2 0xf0 0xe3 0xf0 0xe8 0xf0 0xea 0xf0 0xec 0xf0 0xee 0xf0 0xf0 0xf0 0xf2 0xf0 0xf4 0xf0 0xf6 0xf0 0xf7 0xf0 0xf8 0xf0 0xf9 0xf0 0xfa 0xf1 0x0 0xf1 0x1 0xf1 0x2 0xf1 0x3 0xf1 0x4 0xf1 0x5 0xf1 0x6 0xf1 0x7 0xf1 0x8 0xf1 0xc 0xf1 0x10 0xf1 0x14 0xf1 0x15 0xf1 0x16 0xf1 0x18 0xf1 0x1a 0xf1 0x1c 0xf1 0x1e 0xf1 0x1f 0xf1 0x20 0xf1 0x22 0xf1 0x24 0xf1 0x26 0xf1 0x28 0xf1 0x2a 0xf1 0x2c 0xf1 0x2e 0xf1 0x30 0xf1 0x32 0xf1 0x34 0xf1 0x36 0xf1 0x38 0xf1 0x3a 0xf1 0x3c 0xf1 0x3e 0xf1 0x40 0xf1 0x42 0xf1 0x44 0xf1 0x46 0xf1 0x48 0xf1 0x4a 0xf1 0x4c 0xf1 0x4e 0xf1 0x50 0xf1 0x52 0xf1 0x54 0xf1 0x56 0xf1 0x58 0xf1 0x5a 0xf1 0x5c 0xf1 0x5e 0xf1 0x60 0xf1 0x62 0xf1 0x63 0xf1 0x64 0xf1 0x66 0xf1 0x68 0xf1 0x6a 0xf1 0x6c 0xf1 0x6e 0xf1 0x70>;
				};
			};
		};
	};

	gen-vkeys {
		compatible = "qcom,gen-vkeys";
		label = "ft5x06_ts";
		qcom,disp-maxx = <0x1e0>;
		qcom,disp-maxy = <0x356>;
		qcom,panel-maxx = <0x1e1>;
		qcom,panel-maxy = <0x3b2>;
		qcom,key-codes = <0x8b 0xac 0x9e>;
		qcom,y-offset = <0x0>;
	};

	gpio_keys {
		compatible = "gpio-keys";
		input-name = "gpio-keys";
		pinctrl-names = "tlmm_gpio_key_active","tlmm_gpio_key_suspend";
		pinctrl-0 = <&gpio_key_active>;
		pinctrl-1 = <&gpio_key_suspend>;

		camera_focus {
			label = "camera_focus";
			gpios = <&msm_gpio 91 0x1>;
			linux,input-type = <1>;
			linux,code = <0x210>;
			gpio-key,wakeup;
			debounce-interval = <15>;
		};

		camera_snapshot {
			label = "camera_snapshot";
			gpios = <&msm_gpio 92 0x1>;
			linux,input-type = <1>;
			linux,code = <0x2fe>;
			gpio-key,wakeup;
			debounce-interval = <15>;
		};

		vol_up {
			label = "volume_up";
			gpios = <&msm_gpio 90 0x1>;
			linux,input-type = <1>;
			linux,code = <115>;
			gpio-key,wakeup;
			debounce-interval = <15>;
		};
	};

	audio_codec_mtp: sound {
		compatible = "qcom,msm8x16-audio-codec";
		qcom,model = "msm8909-snd-card";
		qcom,msm-snd-card-id = <0>;
		qcom,msm-codec-type = "internal";
		qcom,msm-ext-pa = "primary";
		qcom,msm-mclk-freq = <9600000>;
		qcom,msm-mbhc-hphl-swh = <0>;
		qcom,msm-mbhc-gnd-swh = <0>;
		qcom,msm-hs-micbias-type = "internal";
		qcom,msm-micbias1-ext-cap;
		qcom,audio-routing =
			"RX_BIAS", "MCLK",
			"SPK_RX_BIAS", "MCLK",
			"INT_LDO_H", "MCLK",
			"MIC BIAS External", "Handset Mic",
			"MIC BIAS Internal2", "Headset Mic",
			"MIC BIAS External", "Secondary Mic",
			"AMIC1", "MIC BIAS External",
			"AMIC2", "MIC BIAS Internal2",
			"AMIC3", "MIC BIAS External";
		pinctrl-names = "cdc_lines_act",
				"cdc_lines_sus",
				"cross_conn_det_act",
				"cross_conn_det_sus",
				"vdd_spkdrv_act",
				"vdd_spkdrv_sus";
		pinctrl-0 = <&cdc_pdm_lines_act &vdd_spkdrv_act>;
		pinctrl-1 = <&cdc_pdm_lines_sus &vdd_spkdrv_sus>;
		pinctrl-2 = <&cross_conn_det_act>;
		pinctrl-3 = <&cross_conn_det_sus>;
		qcom,cdc-us-euro-gpios = <&msm_gpio 97 0>;
		asoc-platform = <&pcm0>, <&pcm1>, <&voip>, <&voice>,
				<&loopback>, <&compress>, <&hostless>,
				<&afe>, <&lsm>, <&routing>, <&lpa>,
				<&voice_svc>;
		asoc-platform-names = "msm-pcm-dsp.0", "msm-pcm-dsp.1",
				"msm-voip-dsp", "msm-pcm-voice", "msm-pcm-loopback",
				"msm-compress-dsp", "msm-pcm-hostless", "msm-pcm-afe",
				"msm-lsm-client", "msm-pcm-routing", "msm-pcm-lpa",
				"msm-voice-svc";
		asoc-cpu = <&dai_pri_auxpcm>, <&dai_hdmi>,
				<&dai_mi2s0>, <&dai_mi2s1>, <&dai_mi2s2>, <&dai_mi2s3>,
				<&sb_0_rx>, <&sb_0_tx>, <&sb_1_rx>, <&sb_1_tx>,
				<&sb_3_rx>, <&sb_3_tx>, <&sb_4_rx>, <&sb_4_tx>,
				<&bt_sco_rx>, <&bt_sco_tx>,<&bt_a2dp_rx>,
                                <&int_fm_rx>, <&int_fm_tx>,
				<&afe_pcm_rx>, <&afe_pcm_tx>, <&afe_proxy_rx>, <&afe_proxy_tx>,
				<&incall_record_rx>, <&incall_record_tx>, <&incall_music_rx>,
				<&incall_music_2_rx>;
		asoc-cpu-names = "msm-dai-q6-auxpcm.1", "msm-dai-q6-hdmi.8",
				"msm-dai-q6-mi2s.0", "msm-dai-q6-mi2s.1",
				"msm-dai-q6-mi2s.2", "msm-dai-q6-mi2s.3",
				"msm-dai-q6-dev.16384", "msm-dai-q6-dev.16385",
				"msm-dai-q6-dev.16386", "msm-dai-q6-dev.16387",
				"msm-dai-q6-dev.16390", "msm-dai-q6-dev.16391",
				"msm-dai-q6-dev.16392", "msm-dai-q6-dev.16393",
				"msm-dai-q6-dev.12288", "msm-dai-q6-dev.12289",
				"msm-dai-q6-dev.12290", "msm-dai-q6-dev.12292",
                                "msm-dai-q6-dev.12293", "msm-dai-q6-dev.224",
				"msm-dai-q6-dev.225", "msm-dai-q6-dev.241",
				"msm-dai-q6-dev.240", "msm-dai-q6-dev.32771",
				"msm-dai-q6-dev.32772", "msm-dai-q6-dev.32773",
                                "msm-dai-q6-dev.32770";
		asoc-codec = <&stub_codec>, <&pm8909_conga_dig>;
		asoc-codec-names = "msm-stub-codec.1", "tombak_codec";
	};
};

&blsp1_uart1 {
	status = "disabled";
	pinctrl-names = "default";
	pinctrl-0 = <&uart_console_sleep>;
};

&qcom_rng {
	status = "okay";
};

&qcom_crypto {
	status = "okay";
};

&qcom_cedev {
	status = "okay";
};

&qcom_seecom {
	status = "okay";
};

&qcom_tzlog {
	status = "okay";
};

&sdhc_1 {
	vdd-supply = <&pm8909_l8>;
	qcom,vdd-voltage-level = <2900000 2900000>;
	qcom,vdd-current-level = <200 400000>;

	vdd-io-supply = <&pm8909_l5>;
	qcom,vdd-io-always-on;
	qcom,vdd-io-lpm-sup;
	qcom,vdd-io-voltage-level = <1800000 1800000>;
	qcom,vdd-io-current-level = <200 60000>;

	pinctrl-names = "active", "sleep";
	pinctrl-0 = <&sdc1_clk_on &sdc1_cmd_on &sdc1_data_on>;
	pinctrl-1 = <&sdc1_clk_off &sdc1_cmd_off &sdc1_data_off>;

	qcom,bus-speed-mode = "HS200_1p8v", "DDR_1p8v";
	qcom,nonremovable;

	status = "ok";
};

&sdhc_2 {
	 #address-cells = <0>;
	interrupt-parent = <&sdhc_2>;
	interrupts = <0 1 2>;
	#interrupt-cells = <1>;
	interrupt-map-mask = <0xffffffff>;
	interrupt-map = <0 &intc 0 125 0
			1 &intc 0 221 0
			2 &msm_gpio 38 0>;
	interrupt-names = "hc_irq", "pwr_irq", "status_irq";
	cd-gpios = <&msm_gpio 38 0x1>;

	vdd-supply = <&pm8909_l11>;
	qcom,vdd-voltage-level = <1800000 2950000>;
	qcom,vdd-current-level = <15000 400000>;

	vdd-io-supply = <&pm8909_l12>;
	qcom,vdd-io-voltage-level = <1800000 2950000>;
	qcom,vdd-io-current-level = <200 50000>;

	pinctrl-names = "active", "sleep";
	pinctrl-0 = <&sdc2_clk_on &sdc2_cmd_on &sdc2_data_on &sdc2_cd_on>;
	pinctrl-1 = <&sdc2_clk_off &sdc2_cmd_off &sdc2_data_off &sdc2_cd_off>;

	status = "ok";
};

&tlmm_pinmux {
	cm36686_int_pin {
		qcom,pins = <&gp 0x5e>;
		qcom,pin-func = <0x0>;
		qcom,num-grp-pins = <1>;
		label = "cm36686-irq";

		cm36686_default: cm36686_default {
			drive-strength = <6>;
			bias-pull-up;
		};
	};
};

&i2c_1 { /* BLSP1 QUP1 */
	mcube@4c {
		compatible = "mcube,mc3xxx";
		reg = <0x4c>;
		vdd-supply = <&pm8909_l17>;
		vio-supply = <&pm8909_l6>;
		mcube,min-interval = <0x5>;
		mcube,init-interval = <0xc8>;
		mcube,axis-map-x = <0x1>;
		mcube,axis-map-y = <0x0>;
		mcube,axis-map-z = <0x2>;
		mcube,g-range = <0x8>;
		mcube,negate-x;
		mcube,negate-y;
		mcube,negate-z;
		mcube,res-14bit;
	};

	capella@60 {
		compatible = "capella,cm36686";
		reg = <0x60>;
		pinctrl-names = "default";
		pinctrl-0 = <&cm36686_default>;
		interrupt-parent = <&msm_gpio>;
		interrupts = <0x5e 0x2>;
		vdd-supply = <&pm8909_l17>;
		vio-supply = <&pm8909_l6>;
		capella,interrupt-gpio = <&msm_gpio 0x5e 0x2>;
		capella,ps_duty = <0x0>;
		capella,ps_it = <0x2>;
		capella,ps_led_drv = <0x2>;
		capella,ps_close_thd_set = <0x32>;
		capella,ps_away_thd_set = <0xf>;
		capella,als_range = <0x0>;
		capella,als_fittness = <0xa>;
		capella,ps_crosstalk_max = <0x46>;
		capella,ps_crosstalk_min = <0x0>;
	};
};

#include "dsi-panel-ili9806e-dijing_boe_fwvga-video.dtsi"
#include "dsi-panel-ili9806e-htl_hsd_fwvga-video.dtsi"
#include "dsi-panel-ili9806e-txd_boe_fwvga-video.dtsi"

&mdss_mdp {
	qcom,mdss-pref-prim-intf = "dsi";
};

&pmx_mdss {
	qcom,num-grp-pins = <2>;
	qcom,pins = <&gp 25>, <&gp 37>;
};

&pmx_mdss_te {
	qcom,num-grp-pins = <1>;
	qcom,pins = <&gp 24>;
};

&mdss_dsi0 {
	qcom,dsi-pref-prim-pan = <&dsi_ili9806e_txd_boe_fwvga_video>;
	pinctrl-names = "mdss_default", "mdss_sleep";
	pinctrl-0 = <&mdss_dsi_active &mdss_te_active>;
	pinctrl-1 = <&mdss_dsi_suspend &mdss_te_suspend>;

	qcom,platform-reset-gpio = <&msm_gpio 25 0>;
	qcom,platform-bklight-en-gpio = <&msm_gpio 37 0>;
};

/* CoreSight */
&tpiu {
	pinctrl-names = "sdcard", "trace", "swduart",
			"swdtrc", "jtag", "spmi";
	/* NIDnT */
	pinctrl-0 = <&qdsd_clk_sdcard &qdsd_cmd_sdcard
		     &qdsd_data0_sdcard &qdsd_data1_sdcard
		     &qdsd_data2_sdcard &qdsd_data3_sdcard>;
	pinctrl-1 = <&qdsd_clk_trace &qdsd_cmd_trace
		     &qdsd_data0_trace &qdsd_data1_trace
		     &qdsd_data2_trace &qdsd_data3_trace>;
	pinctrl-2 = <&qdsd_cmd_swduart &qdsd_data0_swduart
		     &qdsd_data1_swduart &qdsd_data2_swduart
		     &qdsd_data3_swduart>;
	pinctrl-3 = <&qdsd_clk_swdtrc &qdsd_cmd_swdtrc
		     &qdsd_data0_swdtrc &qdsd_data1_swdtrc
		     &qdsd_data2_swdtrc &qdsd_data3_swdtrc>;
	pinctrl-4 = <&qdsd_cmd_jtag &qdsd_data0_jtag
		     &qdsd_data1_jtag &qdsd_data2_jtag
		     &qdsd_data3_jtag>;
	pinctrl-5 = <&qdsd_clk_spmi &qdsd_cmd_spmi
		     &qdsd_data0_spmi &qdsd_data3_spmi>;
};

&usb_otg{
	vbus_otg-supply = <&smb1360_otg_vreg>;
};
